# M067 register map
File version: 0.1
Registers are 32-bit, read-write, reset 0x0 unless marked. A register's access mark holds for its fields unless they carry their own. Offsets are from the block's base; [hi:lo] are bit positions; {n}, {i} and the like mark numbered series.

## I2C0 — I2C
Base 0x400A0000
Same registers: I2C1 0x400A1000
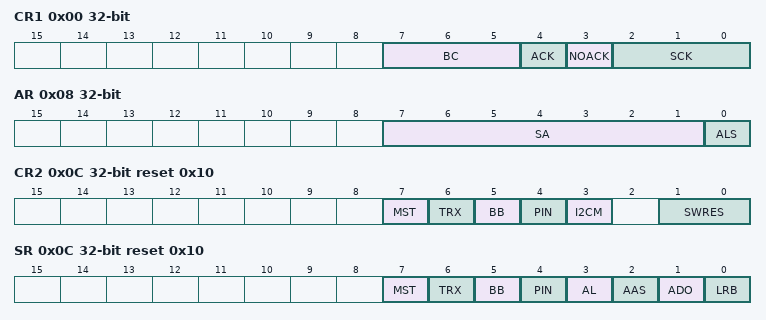
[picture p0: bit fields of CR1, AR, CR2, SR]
0x00 CR1 — I2C Control Register 1
  [7:5] BC, [4] ACK, [3] NOACK, [2:0] SCK
0x04 DBR — Data Buffer Register
  [7:0] DB
0x08 AR — Bus address Register
  [7:1] SA, [0] ALS
0x0C CR2 wo reset 0x10 — Control Register 2
  [7] MST, [6] TRX, [5] BB, [4] PIN, [3] I2CM, [1:0] SWRES
0x0C SR ro reset 0x10 — Status Register
  [7] MST, [6] TRX, [5] BB, [4] PIN, [3] AL, [2] AAS, [1] ADO, [0] LRB
0x10 PRS — Prescaler clcok setting Register
  [4:0] PRSCK
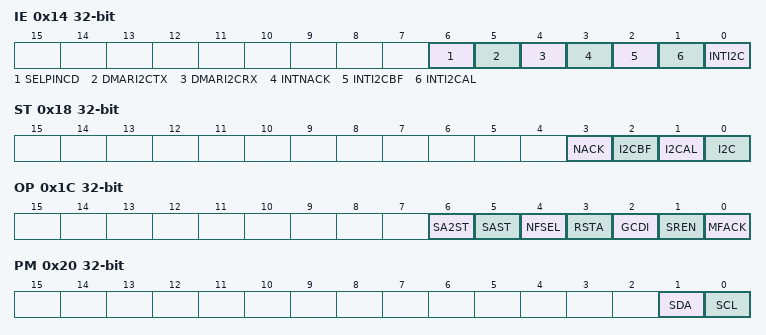
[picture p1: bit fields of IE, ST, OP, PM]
0x14 IE — Interrupt Enable Register
  [6] SELPINCD, [5] DMARI2CTX, [4] DMARI2CRX, [3] INTNACK, [2] INTI2CBF, [1] INTI2CAL, [0] INTI2C
0x18 ST — Interrupt Register
  [3] NACK, [2] I2CBF, [1] I2CAL, [0] I2C
0x1C OP — Optiononal Function register
  [6] SA2ST, [5] SAST, [4] NFSEL, [3] RSTA, [2] GCDI, [1] SREN, [0] MFACK
0x20 PM ro — Bus Monitor register
  [1] SDA, [0] SCL
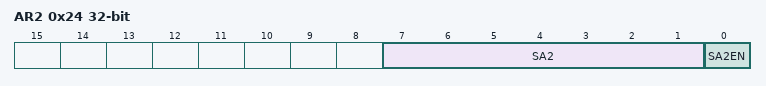
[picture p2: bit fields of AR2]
0x24 AR2 — Second Slave address register
  [7:1] SA2, [0] SA2EN

## PA — Port A
Base 0x400C0000
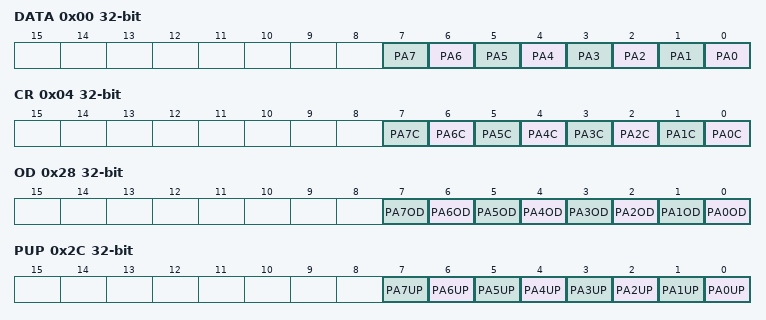
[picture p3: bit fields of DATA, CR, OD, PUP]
0x00 DATA — PA Data Register
  [n] PA{n} (n=0..7)
0x04 CR — PA Control Register
  [n] PA{n}C (n=0..7)
0x08 FR1 — PA Function Register 1
  [7] PA7F1
0x28 OD — PA Open Drain Control Register
  [n] PA{n}OD (n=0..7)
0x2C PUP — PA Pull-up Control Register
  [n] PA{n}UP (n=0..7)
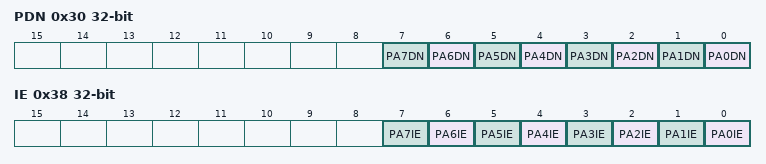
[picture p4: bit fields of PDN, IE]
0x30 PDN — PA Pull-Down Control Register
  [n] PA{n}DN (n=0..7)
0x38 IE — PA Input Enable Control Register
  [n] PA{n}IE (n=0..7)

## PC — Port C
Base 0x400C0200
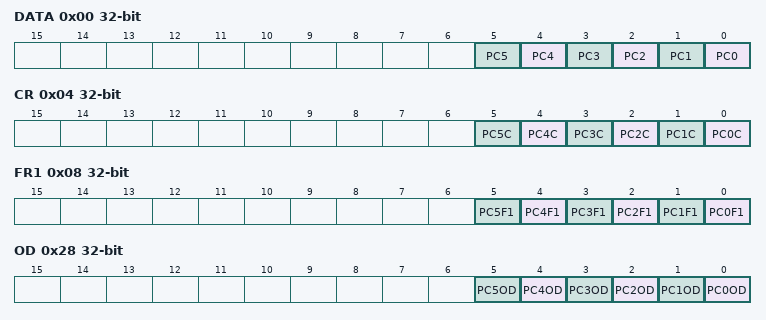
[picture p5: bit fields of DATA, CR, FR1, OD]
0x00 DATA — PC Data Register
  [n] PC{n} (n=0..5)
0x04 CR — PC Control Register
  [n] PC{n}C (n=0..5)
0x08 FR1 — PC Function Register 1
  [n] PC{n}F1 (n=0..5)
0x28 OD — PC Open Drain Control Register
  [n] PC{n}OD (n=0..5)
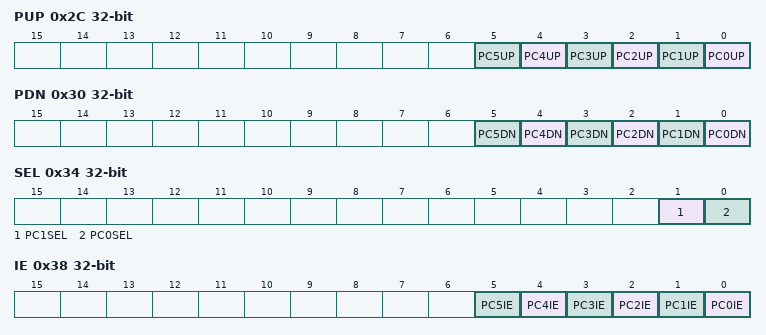
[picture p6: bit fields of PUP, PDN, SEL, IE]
0x2C PUP — PC Pull-up Control Register
  [n] PC{n}UP (n=0..5)
0x30 PDN — PC Pull-Down Control Register
  [n] PC{n}DN (n=0..5)
0x34 SEL — PC input voltage selection Register
  [1] PC1SEL, [0] PC0SEL
0x38 IE — PC Input Enable Control Register
  [n] PC{n}IE (n=0..5)

## PD — Port D
Base 0x400C0300
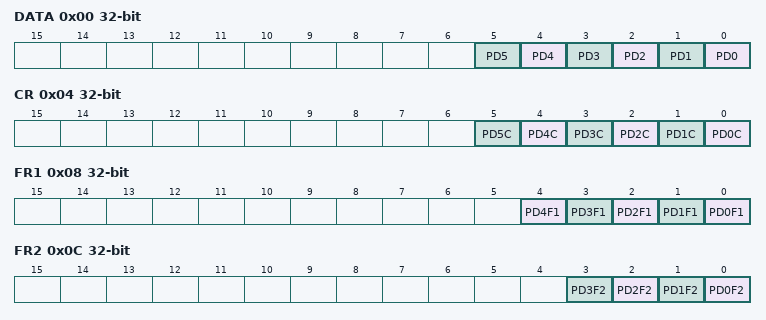
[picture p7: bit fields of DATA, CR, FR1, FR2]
0x00 DATA — PD Data Register
  [n] PD{n} (n=0..5)
0x04 CR — PD Control Register
  [n] PD{n}C (n=0..5)
0x08 FR1 — PD Function Register 1
  [n] PD{n}F1 (n=0..4)
0x0C FR2 — PD Function Register 2
  [n] PD{n}F2 (n=0..3)
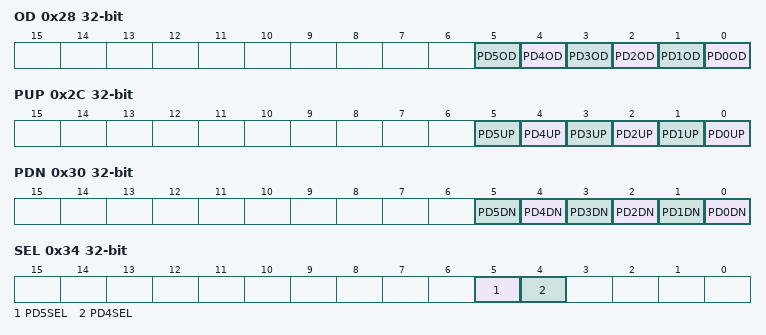
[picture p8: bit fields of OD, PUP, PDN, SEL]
0x28 OD — PD Open Drain Control Register
  [n] PD{n}OD (n=0..5)
0x2C PUP — PD Pull-up Control Register
  [n] PD{n}UP (n=0..5)
0x30 PDN — PD Pull-Down Control Register
  [n] PD{n}DN (n=0..5)
0x34 SEL — PD input voltage selection Register
  [5] PD5SEL, [4] PD4SEL
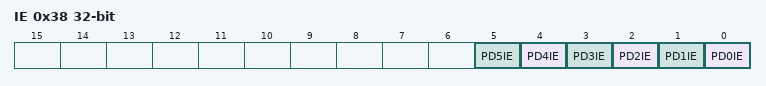
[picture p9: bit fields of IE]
0x38 IE — PD Input Enable Control Register
  [n] PD{n}IE (n=0..5)

## PE — Port E
Base 0x400C0400
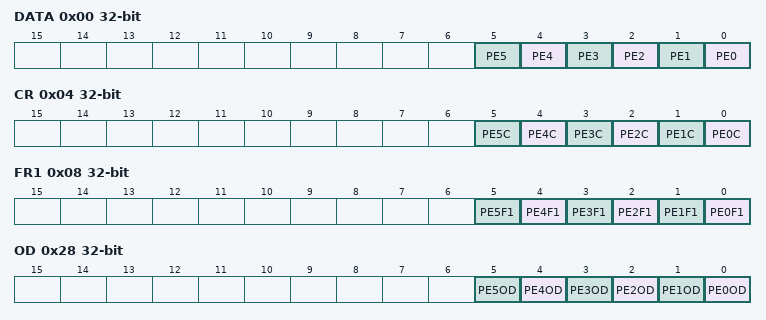
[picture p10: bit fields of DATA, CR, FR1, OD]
0x00 DATA — PE Data Register
  [n] PE{n} (n=0..5)
0x04 CR — PE Control Register
  [n] PE{n}C (n=0..5)
0x08 FR1 — PE Function Register 1
  [n] PE{n}F1 (n=0..5)
0x0C FR2 — PE Function Register 2
  [1] PE1F2
0x28 OD — PE Open Drain Control Register
  [n] PE{n}OD (n=0..5)
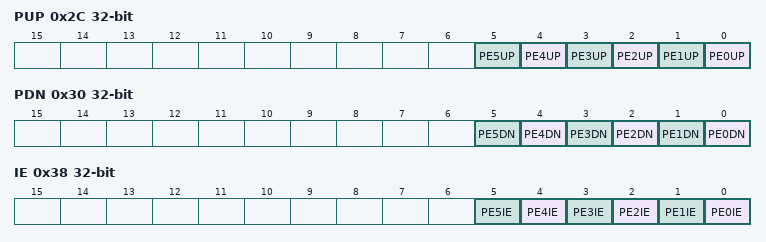
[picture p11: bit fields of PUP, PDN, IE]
0x2C PUP — PE Pull-up Control Register
  [n] PE{n}UP (n=0..5)
0x30 PDN — PE Pull-Down Control Register
  [n] PE{n}DN (n=0..5)
0x38 IE — PE Input Enable Control Register
  [n] PE{n}IE (n=0..5)

## PF — Port F
Base 0x400C0500
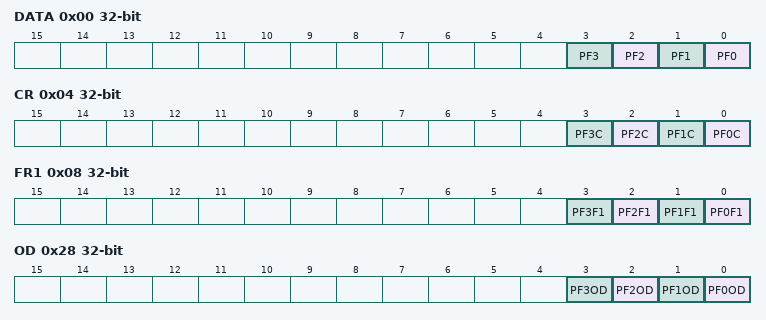
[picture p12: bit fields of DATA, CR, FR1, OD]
0x00 DATA — PF Data Register
  [n] PF{n} (n=0..3)
0x04 CR — PF Control Register
  [n] PF{n}C (n=0..3)
0x08 FR1 — PF Function Register 1
  [n] PF{n}F1 (n=0..3)
0x0C FR2 — PF Function Register 2
  [0] PF0F1
0x28 OD — PF Open Drain Control Register
  [n] PF{n}OD (n=0..3)
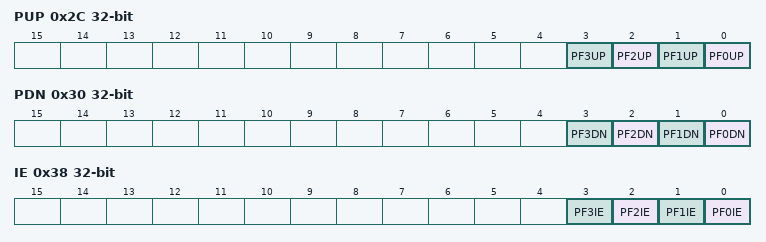
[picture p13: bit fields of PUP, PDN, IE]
0x2C PUP — PF Pull-up Control Register
  [n] PF{n}UP (n=0..3)
0x30 PDN — PF Pull-Down Control Register
  [n] PF{n}DN (n=0..3)
0x38 IE — PF Input Enable Control Register
  [n] PF{n}IE (n=0..3)

## PG — Port G
Base 0x400C0600
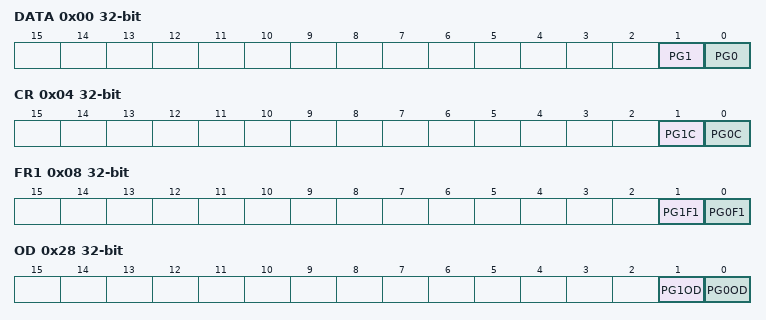
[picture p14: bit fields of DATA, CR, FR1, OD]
0x00 DATA — PG Data Register
  [1] PG1, [0] PG0
0x04 CR — PG Control Register
  [1] PG1C, [0] PG0C
0x08 FR1 — PG Function Register 1
  [1] PG1F1, [0] PG0F1
0x28 OD — PG Open Drain Control Register
  [1] PG1OD, [0] PG0OD
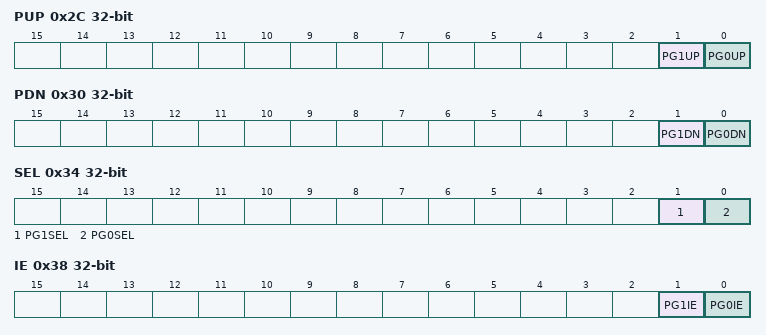
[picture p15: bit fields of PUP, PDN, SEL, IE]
0x2C PUP — PG Pull-up Control Register
  [1] PG1UP, [0] PG0UP
0x30 PDN — PG Pull-Down Control Register
  [1] PG1DN, [0] PG0DN
0x34 SEL — PG input voltage selection Register
  [1] PG1SEL, [0] PG0SEL
0x38 IE — PG Input Enable Control Register
  [1] PG1IE, [0] PG0IE
